# STM32L0x2 register map
File version: 1.7
CPU: CM0+ r0p0, little endian, MPU, no FPU, 2 interrupt priority bits
Registers are 32-bit, read-write, reset 0x0 unless marked. A register's access mark holds for its fields unless they carry their own. Offsets are from the block's base; [hi:lo] are bit positions; 'fields as' and 'values as' point back to an identical list.

## RCC — Reset and clock control
Base 0x40021000
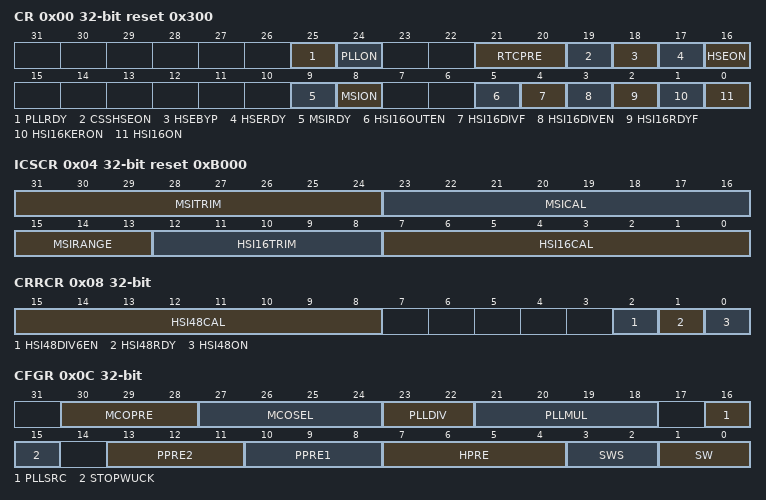
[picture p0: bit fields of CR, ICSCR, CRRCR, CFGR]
0x00 CR access per field reset 0x300 — Clock control register
  [25] PLLRDY ro — PLL clock ready flag
    0=Unlocked (PLL unlocked); 1=Locked (PLL locked)
  [24] PLLON rw — PLL enable bit
    0=Disabled (Clock disabled); 1=Enabled (Clock enabled)
  [21:20] RTCPRE rw — TC/LCD prescaler
    0=Div2 (HSE divided by 2); 1=Div4 (HSE divided by 4); 2=Div8 (HSE divided by 8); 3=Div16 (HSE divided by 16)
  [19] CSSHSEON rw — Clock security system on HSE enable bit
    0=Disabled (Clock disabled); 1=Enabled (Clock enabled)
  [18] HSEBYP rw — HSE clock bypass bit
    0=NotBypassed (HSE oscillator not bypassed); 1=Bypassed (HSE oscillator bypassed)
  [17] HSERDY ro — HSE clock ready flag
    0=NotReady (Oscillator is not stable); 1=Ready (Oscillator is stable)
  [16] HSEON rw — HSE clock enable bit
    0=Disabled (Clock disabled); 1=Enabled (Clock enabled)
  [9] MSIRDY ro — MSI clock ready flag
    values as HSERDY
  [8] MSION rw — MSI clock enable bit
    0=Disabled (Clock disabled); 1=Enabled (Clock enabled)
  [5] HSI16OUTEN rw — 16 MHz high-speed internal clock output enable
    0=Disabled (HSI output clock disabled); 1=Enabled (HSI output clock enabled)
  [4] HSI16DIVF ro
    0=NotDivided (16 MHz HSI clock not divided); 1=Div4 (16 MHz HSI clock divided by 4)
  [3] HSI16DIVEN rw
    0=NotDivided (no 16 MHz HSI division requested); 1=Div4 (16 MHz HSI division by 4 requested)
  [2] HSI16RDYF rw — Internal high-speed clock ready flag
    on read: 0=NotReady (HSI 16 MHz oscillator not ready); 1=Ready (HSI 16 MHz oscillator ready)
  [1] HSI16KERON ro — High-speed internal clock enable bit for some IP kernels
    0=Disabled (Clock disabled); 1=Enabled (Clock enabled)
  [0] HSI16ON rw — 16 MHz high-speed internal clock enable
    0=Disabled (Clock disabled); 1=Enabled (Clock enabled)
0x04 ICSCR access per field reset 0xB000 — Internal clock sources calibration register
  [31:24] MSITRIM rw — MSI clock trimming
  [23:16] MSICAL ro — MSI clock calibration
  [15:13] MSIRANGE rw — MSI clock ranges
    0=range 0 around 65.536 kHz; 1=range 1 around 131.072 kHz; 2=range 2 around 262.144 kHz; 3=range 3 around 524.288 kHz; 4=range 4 around 1.048 MHz; 5=range 5 around 2.097 MHz (reset value); 6=range 6 around 4.194 MHz; 7=Range7 (not allowed)
  [12:8] HSI16TRIM rw — High speed internal clock trimming
  [7:0] HSI16CAL ro — nternal high speed clock calibration
0x08 CRRCR access per field — Clock recovery RC register
  [15:8] HSI48CAL ro — 48 MHz HSI clock calibration
  [2] HSI48DIV6EN rw — 48 MHz HSI clock divided by 6 output enable
  [1] HSI48RDY ro — 48MHz HSI clock ready flag
  [0] HSI48ON rw — 48MHz HSI clock enable bit
0x0C CFGR access per field — Clock configuration register
  [30:28] MCOPRE rw — Microcontroller clock output prescaler
    0=Div1 (No division); 1=Div2 (Division by 2); 2=Div4 (Division by 4); 3=Div8 (Division by 8); 4=Div16 (Division by 16)
  [27:24] MCOSEL rw — Microcontroller clock output selection
    0=NoClock; 1=SYSCLK (SYSCLK clock selected); 2=HSI16 (HSI oscillator clock selected); 3=MSI (MSI oscillator clock selected); 4=HSE (HSE oscillator clock selected); 5=PLL (PLL clock selected); 6=LSI (LSI oscillator clock selected); 7=LSE (LSE oscillator clock selected)
  [23:22] PLLDIV rw — PLL output division
    1=Div2 (PLLVCO / 2); 2=Div3 (PLLVCO / 3); 3=Div4 (PLLVCO / 4)
  [21:18] PLLMUL rw — PLL multiplication factor
    0=Mul3 (PLL clock entry x 3); 1=Mul4 (PLL clock entry x 4); 2=Mul6 (PLL clock entry x 6); 3=Mul8 (PLL clock entry x 8); 4=Mul12 (PLL clock entry x 12); 5=Mul16 (PLL clock entry x 16); 6=Mul24 (PLL clock entry x 24); 7=Mul32 (PLL clock entry x 32); 8=Mul48 (PLL clock entry x 48)
  [16] PLLSRC rw — PLL entry clock source
    0=HSI16 (HSI selected as PLL input clock); 1=HSE (HSE selected as PLL input clock)
  [15] STOPWUCK rw — Wake-up from stop clock selection
    0=MSI (Internal 64 KHz to 4 MHz (MSI) oscillator selected as wake-up from Stop clock); 1=HSI16 (Internal 16 MHz (HSI) oscillator selected as wake-up from Stop clock (or HSI16/4 if HSI16DIVEN=1))
  [13:11] PPRE2 rw — APB high-speed prescaler (APB2)
    4=Div2 (HCLK divided by 2); 5=Div4 (HCLK divided by 4); 6=Div8 (HCLK divided by 8); 7=Div16 (HCLK divided by 16); other=Div1 (HCLK not divided)
  [10:8] PPRE1 rw — APB low-speed prescaler (APB1)
    values as PPRE2
  [7:4] HPRE rw — AHB prescaler
    8=Div2 (system clock divided by 2); 9=Div4 (system clock divided by 4); 10=Div8 (system clock divided by 8); 11=Div16 (system clock divided by 16); 12=Div64 (system clock divided by 64); 13=Div128 (system clock divided by 128); 14=Div256 (system clock divided by 256); 15=Div512 (system clock divided by 512); other=Div1 (system clock not divided)
  [3:2] SWS ro — System clock switch status
    0=MSI (MSI oscillator used as system clock); 1=HSI16 (HSI oscillator used as system clock); 2=HSE (HSE oscillator used as system clock); 3=PLL (PLL used as system clock)
  [1:0] SW rw — System clock switch
    values as SWS
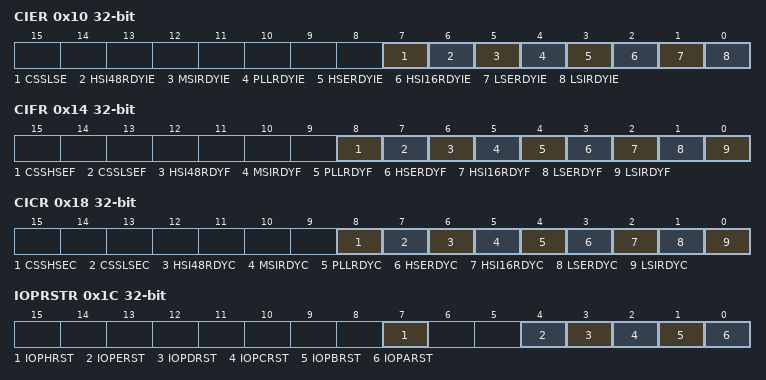
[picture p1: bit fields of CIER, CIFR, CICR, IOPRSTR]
0x10 CIER — Clock interrupt enable register
  [7] CSSLSE — LSE CSS interrupt flag
    0=Disabled (LSE CSS interrupt disabled); 1=Enabled (LSE CSS interrupt enabled)
  [6] HSI48RDYIE — HSI48 ready interrupt flag
    0=Disabled (Ready interrupt disabled); 1=Enabled (Ready interrupt enabled)
  [5] MSIRDYIE — MSI ready interrupt flag
    values as HSI48RDYIE
  [4] PLLRDYIE — PLL ready interrupt flag
    values as HSI48RDYIE
  [3] HSERDYIE — HSE ready interrupt flag
    values as HSI48RDYIE
  [2] HSI16RDYIE — HSI16 ready interrupt flag
    values as HSI48RDYIE
  [1] LSERDYIE — LSE ready interrupt flag
    values as HSI48RDYIE
  [0] LSIRDYIE — LSI ready interrupt flag
    values as HSI48RDYIE
0x14 CIFR ro — Clock interrupt flag register
  [8] CSSHSEF — Clock Security System Interrupt flag
    0=No clock security interrupt caused by HSE clock failure; 1=Clock security interrupt caused by HSE clock failure
  [7] CSSLSEF — LSE Clock Security System Interrupt flag
    0=No failure detected on LSE clock failure; 1=Failure detected on LSE clock failure
  [6] HSI48RDYF — HSI48 ready interrupt flag
    0=NotInterrupted (No clock ready interrupt); 1=Interrupted (Clock ready interrupt)
  [5] MSIRDYF — MSI ready interrupt flag
    values as HSI48RDYF
  [4] PLLRDYF — PLL ready interrupt flag
    values as HSI48RDYF
  [3] HSERDYF — HSE ready interrupt flag
    values as HSI48RDYF
  [2] HSI16RDYF — HSI16 ready interrupt flag
    values as HSI48RDYF
  [1] LSERDYF — LSE ready interrupt flag
    values as HSI48RDYF
  [0] LSIRDYF — LSI ready interrupt flag
    values as HSI48RDYF
0x18 CICR wo — Clock interrupt clear register
  [all] fields
    1=Clear interrupt flag
  [8] CSSHSEC — Clock Security System Interrupt clear
  [7] CSSLSEC — LSE Clock Security System Interrupt clear
  [6] HSI48RDYC — HSI48 ready Interrupt clear
  [5] MSIRDYC — MSI ready Interrupt clear
  [4] PLLRDYC — PLL ready Interrupt clear
  [3] HSERDYC — HSE ready Interrupt clear
  [2] HSI16RDYC — HSI16 ready Interrupt clear
  [1] LSERDYC — LSE ready Interrupt clear
  [0] LSIRDYC — LSI ready Interrupt clear
0x1C IOPRSTR — GPIO reset register
  [all] fields
    1=Reset I/O port
  [7] IOPHRST — I/O port H reset
  [4] IOPERST — I/O port E reset
  [3] IOPDRST — I/O port D reset
  [2] IOPCRST — I/O port A reset
  [1] IOPBRST — I/O port B reset
  [0] IOPARST — I/O port A reset
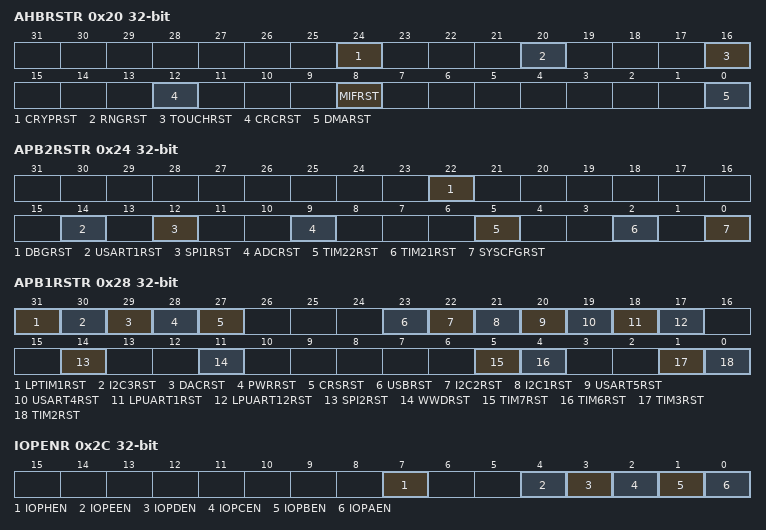
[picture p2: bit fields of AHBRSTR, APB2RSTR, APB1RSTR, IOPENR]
0x20 AHBRSTR — AHB peripheral reset register
  [all] fields
    on write: 1=Reset the module
  [24] CRYPRST — Crypto module reset
  [20] RNGRST — Random Number Generator module reset
  [16] TOUCHRST — Touch Sensing reset
  [12] CRCRST — Test integration module reset
  [8] MIFRST — Memory interface reset
  [0] DMARST — DMA reset
0x24 APB2RSTR — APB2 peripheral reset register
  [all] fields
    on write: 1=Reset the module
  [22] DBGRST — DBG reset
  [14] USART1RST — USART1 reset
  [12] SPI1RST — SPI 1 reset
  [9] ADCRST — ADC interface reset
  [5] TIM22RST — TIM22 timer reset
  [2] TIM21RST — TIM21 timer reset
  [0] SYSCFGRST — System configuration controller reset
0x28 APB1RSTR — APB1 peripheral reset register
  [all] fields
    on write: 1=Reset the module
  [31] LPTIM1RST — Low power timer reset
  [30] I2C3RST — I2C3 reset
  [29] DACRST — DAC interface reset
  [28] PWRRST — Power interface reset
  [27] CRSRST — Clock recovery system reset
  [23] USBRST — USB reset
  [22] I2C2RST — I2C2 reset
  [21] I2C1RST — I2C1 reset
  [20] USART5RST — USART5 reset
  [19] USART4RST — USART4 reset
  [18] LPUART1RST — LPUART1 reset
  [17] LPUART12RST — UART2 reset
  [14] SPI2RST — SPI2 reset
  [11] WWDRST — Window watchdog reset
  [5] TIM7RST — Timer 7 reset
  [4] TIM6RST — Timer 6 reset
  [1] TIM3RST — Timer3 reset
  [0] TIM2RST — Timer2 reset
0x2C IOPENR — GPIO clock enable register
  [all] fields
    0=Disabled (Port clock disabled); 1=Enabled (Port clock enabled)
  [7] IOPHEN — I/O port H clock enable bit
  [4] IOPEEN — I/O port E clock enable bit
  [3] IOPDEN — I/O port D clock enable bit
  [2] IOPCEN — IO port A clock enable bit
  [1] IOPBEN — IO port B clock enable bit
  [0] IOPAEN — IO port A clock enable bit
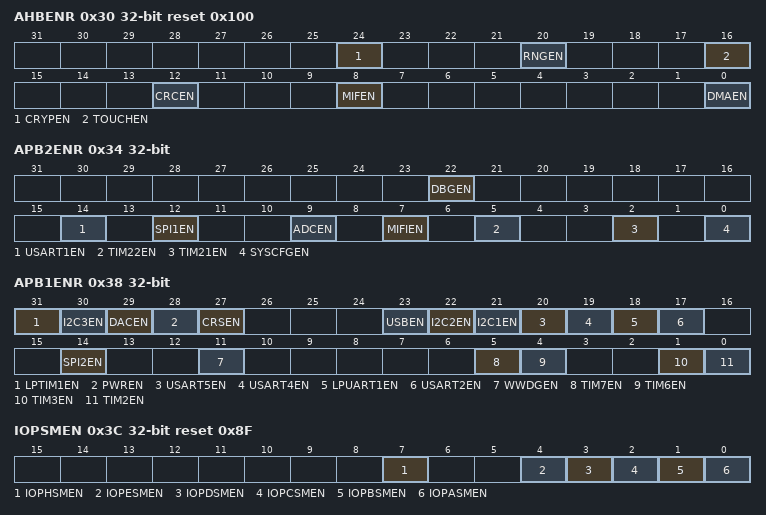
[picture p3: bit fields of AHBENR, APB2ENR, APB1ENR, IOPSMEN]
0x30 AHBENR reset 0x100 — AHB peripheral clock enable register
  [all] fields
    0=Disabled (Clock disabled); 1=Enabled (Clock enabled)
  [24] CRYPEN — Crypto clock enable bit
  [20] RNGEN — Random Number Generator clock enable bit
  [16] TOUCHEN — Touch Sensing clock enable bit
  [12] CRCEN — CRC clock enable bit
  [8] MIFEN — NVM interface clock enable bit
  [0] DMAEN — DMA clock enable bit
0x34 APB2ENR — APB2 peripheral clock enable register
  [all] fields
    0=Disabled (Clock disabled); 1=Enabled (Clock enabled)
  [22] DBGEN — DBG clock enable bit
  [14] USART1EN — USART1 clock enable bit
  [12] SPI1EN — SPI1 clock enable bit
  [9] ADCEN — ADC clock enable bit
  [7] MIFIEN — MiFaRe Firewall clock enable bit
  [5] TIM22EN — TIM22 timer clock enable bit
  [2] TIM21EN — TIM21 timer clock enable bit
  [0] SYSCFGEN — System configuration controller clock enable bit
0x38 APB1ENR — APB1 peripheral clock enable register
  [all] fields
    0=Disabled (Clock disabled); 1=Enabled (Clock enabled)
  [31] LPTIM1EN — Low power timer clock enable bit
  [30] I2C3EN — I2C3 clock enable bit
  [29] DACEN — DAC interface clock enable bit
  [28] PWREN — Power interface clock enable bit
  [27] CRSEN — Clock recovery system clock enable bit
  [23] USBEN — USB clock enable bit
  [22] I2C2EN — I2C2 clock enable bit
  [21] I2C1EN — I2C1 clock enable bit
  [20] USART5EN — USART5 clock enable bit
  [19] USART4EN — USART4 clock enable bit
  [18] LPUART1EN — LPUART1 clock enable bit
  [17] USART2EN — UART2 clock enable bit
  [14] SPI2EN — SPI2 clock enable bit
  [11] WWDGEN — Window watchdog clock enable bit
  [5] TIM7EN — Timer 7 clock enable bit
  [4] TIM6EN — Timer 6 clock enable bit
  [1] TIM3EN — Timer3 clock enable bit
  [0] TIM2EN — Timer2 clock enable bit
0x3C IOPSMEN reset 0x8F — GPIO clock enable in sleep mode register
  [all] fields
    0=Disabled (Port x clock is disabled in Sleep mode); 1=Enabled (Port x clock is enabled in Sleep mode (if enabled by IOPHEN))
  [7] IOPHSMEN
  [4] IOPESMEN — Port E clock enable during Sleep mode bit
  [3] IOPDSMEN
  [2] IOPCSMEN
  [1] IOPBSMEN
  [0] IOPASMEN
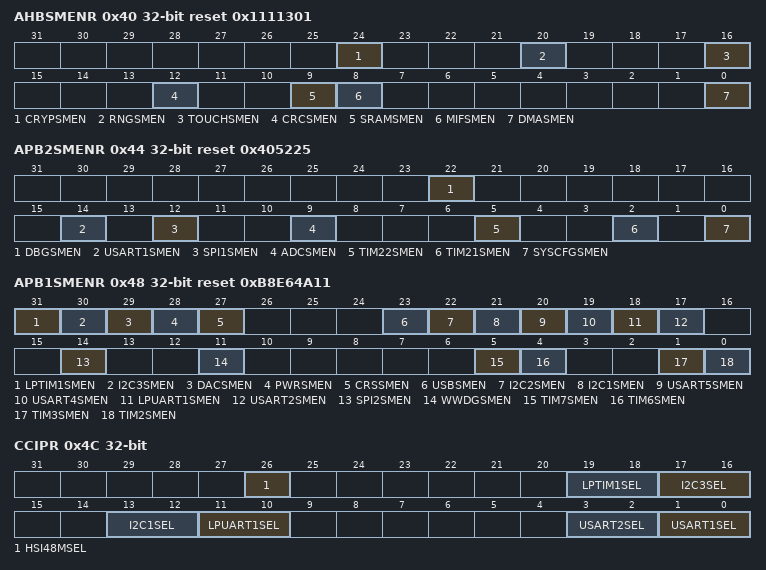
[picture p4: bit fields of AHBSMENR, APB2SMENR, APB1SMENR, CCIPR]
0x40 AHBSMENR reset 0x1111301 — AHB peripheral clock enable in sleep mode register
  [24] CRYPSMEN — Crypto clock enable during sleep mode bit
    0=Disabled (Crypto clock disabled in Sleep mode); 1=Enabled (Crypto clock enabled in Sleep mode)
  [20] RNGSMEN — Random Number Generator clock enable during sleep mode bit
  [16] TOUCHSMEN — Touch Sensing clock enable during sleep mode bit
  [12] CRCSMEN — CRC clock enable during sleep mode bit
    0=Disabled (Test integration module clock disabled in Sleep mode); 1=Enabled (Test integration module clock enabled in Sleep mode (if enabled by CRCEN))
  [9] SRAMSMEN — SRAM interface clock enable during sleep mode bit
    0=Disabled (NVM interface clock disabled in Sleep mode); 1=Enabled (NVM interface clock enabled in Sleep mode)
  [8] MIFSMEN — NVM interface clock enable during sleep mode bit
    values as SRAMSMEN
  [0] DMASMEN — DMA clock enable during sleep mode bit
    0=Disabled (DMA clock disabled in Sleep mode); 1=Enabled (DMA clock enabled in Sleep mode)
0x44 APB2SMENR reset 0x405225 — APB2 peripheral clock enable in sleep mode register
  [all] fields
    0=Disabled (Clock disabled); 1=Enabled (Clock enabled)
  [22] DBGSMEN — DBG clock enable during sleep mode bit
  [14] USART1SMEN — USART1 clock enable during sleep mode bit
  [12] SPI1SMEN — SPI1 clock enable during sleep mode bit
  [9] ADCSMEN — ADC clock enable during sleep mode bit
  [5] TIM22SMEN — TIM22 timer clock enable during sleep mode bit
  [2] TIM21SMEN — TIM21 timer clock enable during sleep mode bit
  [0] SYSCFGSMEN — System configuration controller clock enable during sleep mode bit
0x48 APB1SMENR reset 0xB8E64A11 — APB1 peripheral clock enable in sleep mode register
  [all] fields
    0=Disabled (Clock disabled); 1=Enabled (Clock enabled)
  [31] LPTIM1SMEN — Low power timer clock enable during sleep mode bit
  [30] I2C3SMEN — 2C3 clock enable during Sleep mode bit
  [29] DACSMEN — DAC interface clock enable during sleep mode bit
  [28] PWRSMEN — Power interface clock enable during sleep mode bit
  [27] CRSSMEN — Clock recovery system clock enable during sleep mode bit
  [23] USBSMEN — USB clock enable during sleep mode bit
  [22] I2C2SMEN — I2C2 clock enable during sleep mode bit
  [21] I2C1SMEN — I2C1 clock enable during sleep mode bit
  [20] USART5SMEN — USART5 clock enable during Sleep mode bit
  [19] USART4SMEN — USART4 clock enable during Sleep mode bit
  [18] LPUART1SMEN — LPUART1 clock enable during sleep mode bit
  [17] USART2SMEN — UART2 clock enable during sleep mode bit
  [14] SPI2SMEN — SPI2 clock enable during sleep mode bit
  [11] WWDGSMEN — Window watchdog clock enable during sleep mode bit
  [5] TIM7SMEN — Timer 7 clock enable during Sleep mode bit
  [4] TIM6SMEN — Timer 6 clock enable during sleep mode bit
  [1] TIM3SMEN — Timer3 clock enable during Sleep mode bit
  [0] TIM2SMEN — Timer2 clock enable during sleep mode bit
0x4C CCIPR — Clock configuration register
  [26] HSI48MSEL — 48 MHz HSI48 clock source selection bit
  [19:18] LPTIM1SEL — Low Power Timer clock source selection bits
    0=APB (APB clock selected as Timer clock); 1=LSI (LSI clock selected as Timer clock); 2=HSI16 (HSI16 clock selected as Timer clock); 3=LSE (LSE clock selected as Timer clock)
  [17:16] I2C3SEL — I2C3 clock source selection bits
    0=APB (APB clock selected as peripheral clock); 1=SYSTEM (System clock selected as peripheral clock); 2=HSI16 (HSI16 clock selected as peripheral clock)
  [13:12] I2C1SEL — I2C1 clock source selection bits
    values as I2C3SEL
  [11:10] LPUART1SEL — LPUART1 clock source selection bits
    0=APB (APB clock selected as peripheral clock); 1=SYSTEM (System clock selected as peripheral clock); 2=HSI16 (HSI16 clock selected as peripheral clock); 3=LSE (LSE clock selected as peripheral clock)
  [3:2] USART2SEL — USART2 clock source selection bits
    values as LPUART1SEL
  [1:0] USART1SEL — USART1 clock source selection bits
    values as LPUART1SEL
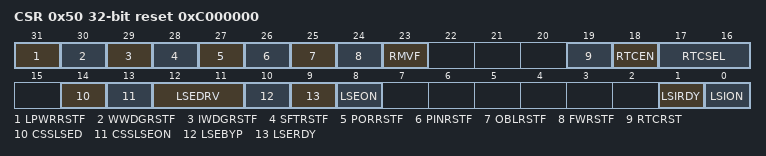
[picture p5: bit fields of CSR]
0x50 CSR access per field reset 0xC000000 — Control and status register
  [31] LPWRRSTF ro — Low-power reset flag
    0=No reset has occured; 1=Reset (A reset has occured)
  [30] WWDGRSTF ro — Window watchdog reset flag
    0=No reset has occured; 1=Reset (A reset has occured)
  [29] IWDGRSTF ro — Independent watchdog reset flag
    0=No reset has occured; 1=Reset (A reset has occured)
  [28] SFTRSTF ro — Software reset flag
    0=No reset has occured; 1=Reset (A reset has occured)
  [27] PORRSTF ro — POR/PDR reset flag
    0=No reset has occured; 1=Reset (A reset has occured)
  [26] PINRSTF ro — PIN reset flag
    0=No reset has occured; 1=Reset (A reset has occured)
  [25] OBLRSTF ro
    0=No reset has occured; 1=Reset (A reset has occured)
  [24] FWRSTF ro — : Firewall reset flag
    0=No reset has occured; 1=Reset (A reset has occured)
  [23] RMVF rw — Remove reset flag
    on write: 1=Clears the reset flag
  [19] RTCRST rw — RTC software reset bit
    on write: 1=Resets the RTC peripheral
  [18] RTCEN rw — RTC clock enable bit
    0=Disabled (RTC clock disabled); 1=Enabled (RTC clock enabled)
  [17:16] RTCSEL rw — RTC and LCD clock source selection bits
    0=NoClock; 1=LSE (LSE oscillator clock used as RTC clock); 2=LSI (LSI oscillator clock used as RTC clock); 3=HSE (HSE oscillator clock divided by a programmable prescaler (selection through the RTCPRE[1:0] bits in the RCC clock control register (RCC_CR)) used as the RTC clock)
  [14] CSSLSED ro — CSS on LSE failure detection flag
    0=No failure detected on LSE (32 kHz oscillator); 1=Failure detected on LSE (32 kHz oscillator)
  [13] CSSLSEON rw
    0=Off (Oscillator OFF); 1=On (Oscillator ON)
  [12:11] LSEDRV rw
    0=Low (Lowest drive); 1=Medium low drive; 2=Medium high drive; 3=Highest drive
  [10] LSEBYP rw — External low-speed oscillator bypass bit
    0=NotBypassed (LSE oscillator not bypassed); 1=Bypassed (LSE oscillator bypassed)
  [9] LSERDY ro — External low-speed oscillator ready bit
    0=NotReady (Oscillator not ready); 1=Ready (Oscillator ready)
  [8] LSEON rw — External low-speed oscillator enable bit
    0=Off (Oscillator OFF); 1=On (Oscillator ON)
  [1] LSIRDY ro — Internal low-speed oscillator ready bit
    values as LSERDY
  [0] LSION rw — Internal low-speed oscillator enable
    0=Off (Oscillator OFF); 1=On (Oscillator ON)
